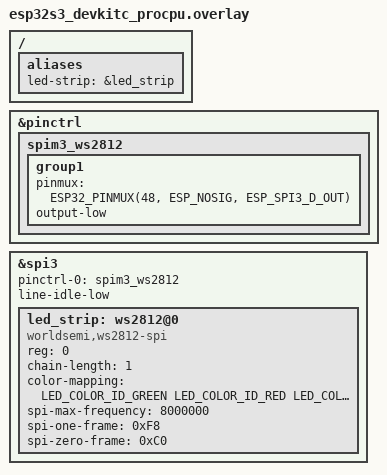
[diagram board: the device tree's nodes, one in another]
#include <zephyr/dt-bindings/led/led.h>

/ {
	aliases {
		led-strip = &led_strip;
	};
};

&pinctrl {
	spim3_ws2812: spim3_ws2812 {
		group1 {
			/* GPIO48 on board rev v1.0, GPIO38 on v1.1 */
			pinmux = <ESP32_PINMUX(48, ESP_NOSIG, ESP_SPI3_D_OUT)>;
			output-low;
		};
	};
};

&spi3 {
	status = "okay";
	pinctrl-0 = <&spim3_ws2812>;
	pinctrl-names = "default";
    /* --- CRITICAL FIX: Keep MOSI low when idle --- */
    line-idle-low;

	led_strip: ws2812@0 {
		compatible = "worldsemi,ws2812-spi";
		reg = <0>;
		chain-length = <1>;
		color-mapping = <LED_COLOR_ID_GREEN LED_COLOR_ID_RED LED_COLOR_ID_BLUE>;
		
        /* NOTES FOR FUTURE ME
        
            The spi-one-frame and spi-zero-frame properties define the bit patterns shifted out to 
            represent a WS2812 '1' or '0'. Their correct values are directly tied to the SPI clock
            frequency.

            At 4 MHz, one SPI bit period is 250 ns. Your working values (0xF0 and 0xC0) produced the
            required pulse widths.

            At 8 MHz, one SPI bit period is halved to 125 ns. To generate the same WS2812 pulse widths, 
            you need to use more SPI bits.

            spi-one-frame = <0xF8> (11111000): This creates a high pulse of 5 bits (5 × 125 ns = 625 ns)
            followed by a low of 3 bits (375 ns).

            spi-zero-frame = <0xC0> (11000000): This creates a high pulse of 2 bits (2 × 125 ns = 250 ns)
            followed by a low of 6 bits (750 ns).

            These timings fall comfortably within the tolerances for most WS2812/WS2812B LEDs. 
            It's worth noting that the official Zephyr sample for the ESP32-S3 uses a slightly lower 
            speed of 6.4 MHz with 0xF0 and 0xC0, which suggests that while 8 MHz is achievable, 
            it requires more precise tuning of these SPI bits, but this firmware achieved the end objetive of:
            red, blue, and off.
        */
            
        // CHANGED FOR 4MHz
		//spi-max-frequency = <4000000>;
        //spi-one-frame = <0xF0>;
        //spi-zero-frame = <0xC0>;

        // CHANGED FOR 8 MHz 
        spi-max-frequency = <8000000>; // Increased from 4 MHz
        spi-one-frame = <0xF8>;        // 11111000: 625 ns high, 375 ns low
        spi-zero-frame = <0xC0>;       // 11000000: 250 ns high, 750 ns low
	};
};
